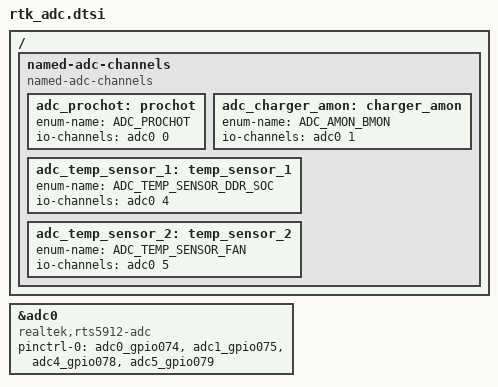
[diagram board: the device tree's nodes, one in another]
/* Copyright 2025 The ChromiumOS Authors
 * Use of this source code is governed by a BSD-style license that can be
 * found in the LICENSE file.
 */

/ {

	named-adc-channels {
		compatible = "named-adc-channels";

		adc_prochot: prochot {
			enum-name = "ADC_PROCHOT";
			io-channels = <&adc0 0>;
		};
		adc_charger_amon: charger_amon {
			enum-name = "ADC_AMON_BMON";
			io-channels = <&adc0 1>;
		};
		adc_temp_sensor_1: temp_sensor_1 {
			enum-name = "ADC_TEMP_SENSOR_DDR_SOC";
			io-channels = <&adc0 4>;
		};
		adc_temp_sensor_2: temp_sensor_2 {
			enum-name = "ADC_TEMP_SENSOR_FAN";
			io-channels = <&adc0 5>;
		};
	};
};

&adc0 {
	compatible = "realtek,rts5912-adc";
	pinctrl-0 = <&adc0_gpio074
		&adc1_gpio075
		&adc4_gpio078
		&adc5_gpio079
	>;
	pinctrl-names = "default";
	status = "okay";
};
